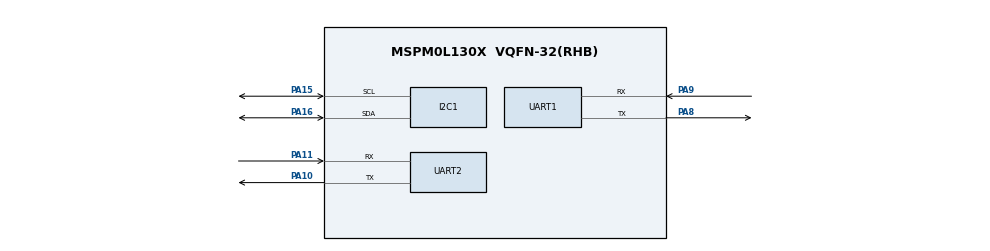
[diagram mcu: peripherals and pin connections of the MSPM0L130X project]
/**
 * @cliArgs --device "MSPM0L130X" --package "VQFN-32(RHB)" --part "Default" --product "mspm0_sdk@1.20.01.06"
 * @versions {"tool":"1.18.1+3343"}
 */

/**
 * Import the modules used in this configuration.
 */
const Board  = scripting.addModule("/ti/driverlib/Board");
const GPIO   = scripting.addModule("/ti/driverlib/GPIO", {}, false);
const GPIO1  = GPIO.addInstance();
const I2C    = scripting.addModule("/ti/driverlib/I2C", {}, false);
const I2C1   = I2C.addInstance();
const SYSCTL = scripting.addModule("/ti/driverlib/SYSCTL");
const TIMER  = scripting.addModule("/ti/driverlib/TIMER", {}, false);
const TIMER1 = TIMER.addInstance();
const TIMER2 = TIMER.addInstance();
const UART   = scripting.addModule("/ti/driverlib/UART", {}, false);
const UART1  = UART.addInstance();
const UART2  = UART.addInstance();

/**
 * Write custom configuration values to the imported modules.
 */

GPIO1.$name                          = "GPIO_GRP_0";
GPIO1.associatedPins.create(5);
GPIO1.associatedPins[0].$name        = "CS";
GPIO1.associatedPins[0].assignedPort = "PORTA";
GPIO1.associatedPins[0].initialValue = "SET";
GPIO1.associatedPins[0].ioStructure  = "SD";
GPIO1.associatedPins[0].assignedPin  = "2";
GPIO1.associatedPins[1].$name        = "LED";
GPIO1.associatedPins[1].assignedPort = "PORTA";
GPIO1.associatedPins[1].assignedPin  = "3";
GPIO1.associatedPins[2].assignedPin  = "6";
GPIO1.associatedPins[2].$name        = "D0";
GPIO1.associatedPins[3].$name        = "D1";
GPIO1.associatedPins[3].assignedPin  = "5";
GPIO1.associatedPins[4].$name        = "DC";
GPIO1.associatedPins[4].assignedPin  = "4";

I2C1.$name                           = "I2C_0";
I2C1.basicEnableController           = true;
I2C1.basicControllerStandardBusSpeed = "Fast";
I2C1.peripheral.$assign              = "I2C1";
I2C1.peripheral.sdaPin.$assign       = "PA16";
I2C1.peripheral.sclPin.$assign       = "PA15";
I2C1.sdaPinConfig.$name              = "ti_driverlib_gpio_GPIOPinGeneric2";
I2C1.sdaPinConfig.enableConfig       = true;
I2C1.sdaPinConfig.internalResistor   = "PULL_UP";
I2C1.sclPinConfig.$name              = "ti_driverlib_gpio_GPIOPinGeneric3";
I2C1.sclPinConfig.enableConfig       = true;
I2C1.sclPinConfig.internalResistor   = "PULL_UP";

SYSCTL.MFCLKEn = true;

TIMER1.$name             = "TIMER_0";
TIMER1.timerClkSrc       = "LFCLK";
TIMER1.timerMode         = "PERIODIC";
TIMER1.interrupts        = ["ZERO"];
TIMER1.interruptPriority = "0";
TIMER1.timerStartTimer   = true;
TIMER1.crossTriggerEn    = true;
TIMER1.timerPeriod       = "100 ms";

TIMER2.$name             = "TIMER_1";
TIMER2.timerClkSrc       = "LFCLK";
TIMER2.timerMode         = "PERIODIC";
TIMER2.interrupts        = ["ZERO"];
TIMER2.interruptPriority = "0";
TIMER2.timerPeriod       = "1 s";
TIMER2.crossTriggerEn    = true;

UART1.$name                    = "UART_0";
UART1.enabledInterrupts        = ["RX","RX_TIMEOUT_ERROR"];
UART1.targetBaudRate           = 115200;
UART1.peripheral.$assign       = "UART0";
UART1.peripheral.rxPin.$assign = "PA9";
UART1.peripheral.txPin.$assign = "PA8";
UART1.txPinConfig.$name        = "ti_driverlib_gpio_GPIOPinGeneric0";
UART1.rxPinConfig.$name        = "ti_driverlib_gpio_GPIOPinGeneric1";

UART2.$name                    = "UART_1";
UART2.targetBaudRate           = 115200;
UART2.peripheral.rxPin.$assign = "PA11";
UART2.peripheral.txPin.$assign = "PA10";
UART2.txPinConfig.$name        = "ti_driverlib_gpio_GPIOPinGeneric4";
UART2.rxPinConfig.$name        = "ti_driverlib_gpio_GPIOPinGeneric5";

/**
 * Pinmux solution for unlocked pins/peripherals. This ensures that minor changes to the automatic solver in a future
 * version of the tool will not impact the pinmux you originally saw.  These lines can be completely deleted in order to
 * re-solve from scratch.
 */
Board.peripheral.$suggestSolution            = "DEBUGSS";
Board.peripheral.swclkPin.$suggestSolution   = "PA20";
Board.peripheral.swdioPin.$suggestSolution   = "PA19";
GPIO1.associatedPins[0].pin.$suggestSolution = "PA2";
GPIO1.associatedPins[1].pin.$suggestSolution = "PA3";
GPIO1.associatedPins[2].pin.$suggestSolution = "PA6";
GPIO1.associatedPins[3].pin.$suggestSolution = "PA5";
GPIO1.associatedPins[4].pin.$suggestSolution = "PA4";
SYSCTL.peripheral.$suggestSolution           = "SYSCTL";
TIMER1.peripheral.$suggestSolution           = "TIMG1";
TIMER2.peripheral.$suggestSolution           = "TIMG0";
UART2.peripheral.$suggestSolution            = "UART1";
